AUTOSAR XML (schema 321)
package /ComponentType
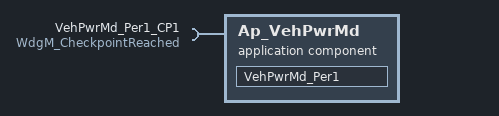
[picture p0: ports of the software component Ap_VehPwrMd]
  application software component type Ap_VehPwrMd
    require port VehPwrMd_Per1_CP1: client-com-spec=CheckpointReached, required-interface=WdgM_CheckpointReached
  internal behavior Ap_VehPwrMd_InternalBehavior: component=Ap_VehPwrMd, port-api-option{enable-take-address=false, indirect-api=false, port=VehPwrMd_Per1_CP1}
    runnable VehPwrMd_Per1
      sync call SC_VehPwrMd_Per1_CP1_CheckpointReached: operation=VehPwrMd_Per1_CP1.CheckpointReached, timeout=0
  swc implementation Ap_VehPwrMd_Implementation: behavior=Ap_VehPwrMd_InternalBehavior
    code-descriptors:
      code Code: type=SRC
package /PortInterface
  client server interface WdgM_CheckpointReached: is-service=true
    operation CheckpointReached: possible-error=E_NOT_OK  # Indicates to the Watchdog Manager that a Checkpoint within a Supervised Entity has been reached.
    error E_NOT_OK: error-code=1
